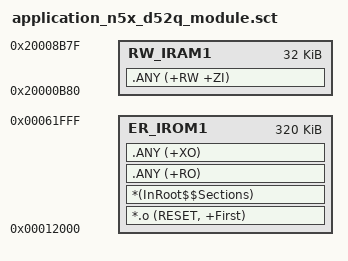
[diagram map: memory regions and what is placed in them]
; ***********************************************************************
; *** Scatter-Loading Description File generated by uv2csolution ***
; ***********************************************************************

LR_IROM1 0x00012000 0x00050000 {    ; load region size_region
  ER_IROM1 0x00012000 0x00050000 {  ; load address = execution address
   *.o (RESET, +First)
   *(InRoot$$Sections)
   .ANY (+RO)
   .ANY (+XO)
  }
  RW_IRAM1 0x20000B80 0x00008000 {  ; RW data
   .ANY (+RW +ZI)
  }
}

